# ATSAMRH707F18A register map
Vendor: Microchip Technology; Series: SAMRH707; File version: 0
CPU: CM7 r1p1, little endian, MPU, FPU, double-precision FPU, I-cache, D-cache, ITCM, DTCM, 3 interrupt priority bits, 69 interrupts
Registers are 32-bit, read-write, reset 0x0 unless marked. A register's access mark holds for its fields unless they carry their own. Offsets are from the block's base; [hi:lo] are bit positions; {n}, {i} and the like mark numbered series.

## HEFC — Harden Embedded Flash Controller
Base 0x40004000
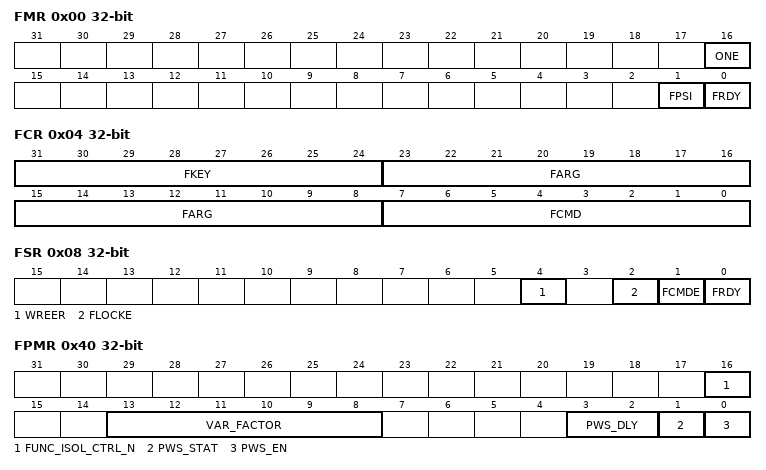
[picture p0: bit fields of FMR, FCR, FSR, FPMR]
0x00 FMR — HEFC Flash Mode Register
  [16] ONE — Must be written to 1
  [1] FPSI — Flash Power Status Interrupt Enable
  [0] FRDY — Flash Ready Interrupt Enable
0x04 FCR wo — HEFC Flash Command Register
  [31:24] FKEY — Flash Writing Protection Key
    90=PASSWD (The 0x5A value enables the command defined by the bits of the register. If the field is written with a different value, the write is not performed and no action is started.)
  [23:8] FARG — Flash Command Argument
  [7:0] FCMD — Flash Command
    0=GETD (Get Flash descriptor); 1=WP (Write page); 2=WPL (Write page and lock); 5=EA (Erase all); 6=EP (Erase page); 7=EPA (Erase pages); 8=SLB (Set lock bit); 9=CLB (Clear lock bit); 10=GLB (Get lock bit); 11=SGPB (Set GPNVM bit); 12=CGPB (Clear GPNVM bit); 13=GGPB (Get GPNVM bit); 16=GCALB (Get CALIB bit); 18=WUS (Write user signature); 19=EUS (Erase user signature); 20=STUS (Start read user signature); 21=SPUS (Stop read user signature)
0x08 FSR ro — HEFC Flash Status Register
  [4] WREER — Write Register Error Status (cleared on read)
  [2] FLOCKE — Flash Lock Error Status (cleared on read)
  [1] FCMDE — Flash Command Error Status (cleared on read or by writing HEFC_FCR)
  [0] FRDY — Flash Ready Status (cleared when Flash is busy)
0x0C FRR ro — HEFC Flash Result Register
  [31:0] FVALUE — Flash Result Value
0x40 FPMR — HEFC Flash Power Management Register
  [16] FUNC_ISOL_CTRL_N — Flash insulated Control Status
  [13:8] VAR_FACTOR — Variation Factor
  [3:2] PWS_DLY — Power switch Delay
    0=_75US (delay is set to 75 usec); 1=_150US (delay is set to 150 usec); 2=_300US (delay is set to 300 usec); 3=_600US (delay is set to 600 usec)
  [1] PWS_STAT — Power switch Status
  [0] PWS_EN — Power switch enable
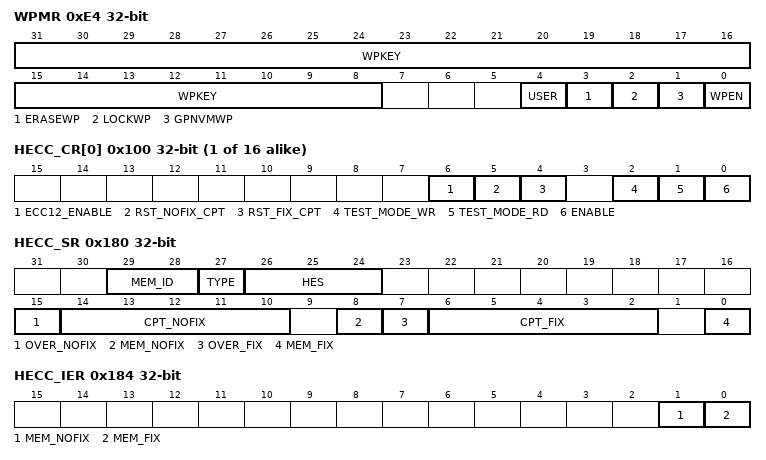
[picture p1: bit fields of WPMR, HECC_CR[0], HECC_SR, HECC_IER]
0xE4 WPMR — Write Protection Mode Register
  [31:8] WPKEY — Write Protection Key
    0x454643=PASSWD (Writing any other value in this field aborts the write operation. Always reads as 0.)
  [4] USER — User Signature Write Protection
  [3] ERASEWP — Page, Sector and Plane Write Protection
  [2] LOCKWP — Lock Bit Write Protection
  [1] GPNVMWP — GPNVM Bit Write Protection
  [0] WPEN — Write Protection Enable
{0x100+4i} HECC_CR[{i}] (i=0..15) — HECC Control Register ChannelNumbers (ChannelNumbers = 0)
  [6] ECC12_ENABLE — BCH ECC enable
  [5] RST_NOFIX_CPT — reset the un-fixable error counter
  [4] RST_FIX_CPT — reset the fixable error counter
  [2] TEST_MODE_WR — test mode of ECC protection - write mode
  [1] TEST_MODE_RD — test mode of ECC protection - read mode
  [0] ENABLE — ECC protection enable
{0x140+4i} HECC_TESTCB[{i}] (i=0..15) — HECC Test mode ChannelNumbers (ChannelNumbers = 0)
  [15:0] TCB — test check bit (16 bit)
0x180 HECC_SR ro — HECC Status register
  [29:28] MEM_ID — memory identification number
  [27] TYPE — write or read access
  [26:24] HES — Hardware Error Size
  [15] OVER_NOFIX — counter overflow
  [14:10] CPT_NOFIX — 5 bits counter
  [8] MEM_NOFIX — Un-fixable error status
  [7] OVER_FIX — counter overflow
  [6:2] CPT_FIX — 5 bits counter
  [0] MEM_FIX — Fixable error status
0x184 HECC_IER wo — HECC Interrupt Enable Register
  [1] MEM_NOFIX — Un-fixable error
  [0] MEM_FIX — Fixable error
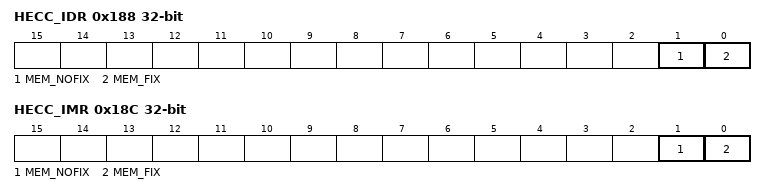
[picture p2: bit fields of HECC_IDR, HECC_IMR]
0x188 HECC_IDR wo — HECC Interrupt Disable Register
  [1] MEM_NOFIX — un-fixable error
  [0] MEM_FIX — fixable error
0x18C HECC_IMR ro — HECC Interrupt Mask Register
  [1] MEM_NOFIX — un-fixable error
  [0] MEM_FIX — fixable error
0x190 HECC_FAILAR ro — HECC Fail address register
  [31:0] ADDRESS — address of the error detected
0x194 HECC_FAILDR ro — HECC Fail data register
  [31:0] DATA — data of the error detected
